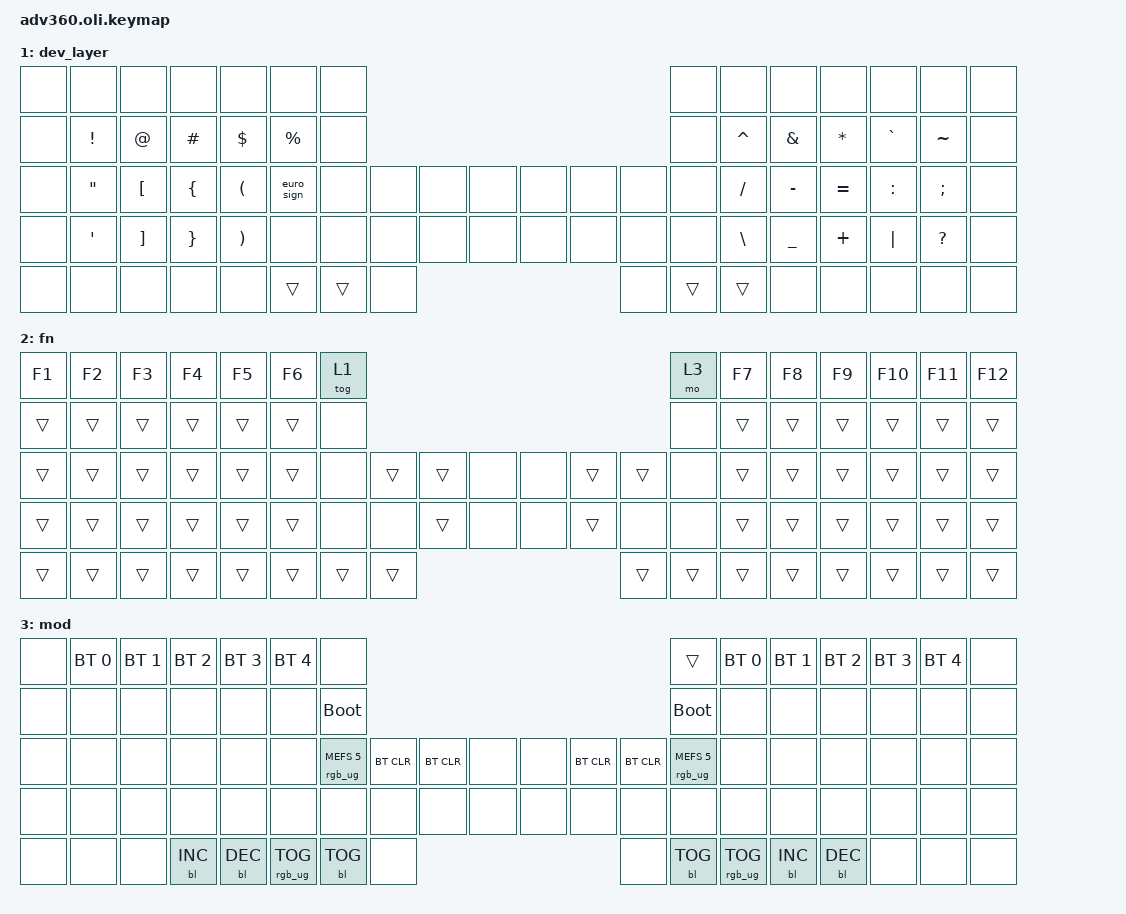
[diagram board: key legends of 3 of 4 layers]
#include <behaviors.dtsi>
#include <dt-bindings/zmk/keys.h>
#include <dt-bindings/zmk/bt.h>
#include <dt-bindings/zmk/rgb.h>
#include <dt-bindings/zmk/backlight.h>

#include "../lib/myHelper.h"
#include "../lib/foreignHelper.h"
#include "../lib/specialChars.dtsi"

// / { 
//     macros {      
//         macro_ue_lower_mac: macro_ue_lower_mac {
//             label = "macro_ue_lower_mac";
//             compatible = "zmk,behavior-macro";
//             wait-ms = <30>;
//             tap-ms = <30>;
//             #binding-cells = <0>;
//             bindings =
//                 <&macro_press &kp LALT>,
//                 <&macro_tap &kp U>,
//                 <&macro_release &kp LALT>,
//                 <&macro_tap &kp U>;
//         };

//         macro_ue_upper_mac: macro_ue_upper_mac {
//             label = "macro_ue_upper_mac";
//             compatible = "zmk,behavior-macro";
//             wait-ms = <20>;
//             tap-ms = <20>;
//             #binding-cells = <0>;
//             bindings =
//                 <&macro_press &kp LALT>,
//                 <&macro_tap &kp U>,
//                 <&macro_release &kp LALT>,
//                 <&macro_tap &kp LC(U)>;
//         };

//         // ZMK_MACRO(ue_lower_mac,
//         //     wait-ms = <30>;
//         //     tap-ms = <30>;
//         //     bindings = 
//         //         <&macro_press &kp LALT>,
//         //         <&macro_tap &kp U>,
//         //         <&macro_release &kp LALT>,
//         //         <&kp U>;
//         // )

//         // ZMK_MACRO(ue_upper_mac,
//         //     wait-ms = <30>;
//         //     tap-ms = <30>;
//         //     bindings =
//         //         <&macro_press &kp LALT>,
//         //         <&macro_tap &kp U>,
//         //         <&macro_release &kp LALT>,
//         //         <&kp LC(U)>;
//         // )
//     };
// };

/ {
    behaviors {
        #include "macros.dtsi"
        
        hm: homerow_mods {
            compatible = "zmk,behavior-hold-tap";
            label = "HOMEROW_MODS";
            #binding-cells = <2>;
            tapping-term-ms = <200>;
            quick_tap_ms = <175>;
            flavor = "tap-preferred";
            bindings = 
                <&kp>,
                <&kp>;
        };

        // macro_ue_lower_mac: macro_ue_lower_mac {
        //     label = "macro_ue_lower_mac";
        //     compatible = "zmk,behavior-macro";
        //     wait-ms = <30>;
        //     tap-ms = <30>;
        //     #binding-cells = <0>;
        //     bindings =
        //         <&macro_press &kp LALT>,
        //         <&macro_tap &kp U>,
        //         <&macro_release &kp LALT>,
        //         <&macro_tap &kp U>;
        // };

        // macro_ue_upper_mac: macro_ue_upper_mac {
        //     label = "macro_ue_upper_mac";
        //     compatible = "zmk,behavior-macro";
        //     wait-ms = <20>;
        //     tap-ms = <20>;
        //     #binding-cells = <0>;
        //     bindings =
        //         <&macro_press &kp LALT>,
        //         <&macro_tap &kp U>,
        //         <&macro_release &kp LALT>,
        //         <&macro_tap &kp LC(U)>;
        // };

        ht: hold_tap {
            label = "hold_tap";
            compatible = "zmk,behavior-hold-tap";
            #binding-cells = <2>;
            flavor = "tap-preferred";
            tapping-term-ms = <200>;
            quick-tap-ms = <160>;
            global-quick-tap;
            bindings = 
                <&kp>,
                <&kp>;
        };

        hts: hold_tap_s {
            label = "hold_tap_s";
            compatible = "zmk,behavior-hold-tap";
            #binding-cells = <2>;
            flavor = "tap-preferred";
            tapping-term-ms = <200>;
            quick-tap-ms = <160>;
            global-quick-tap;
            bindings = 
                <&ue>,
                <&kp>;
        };

        // my_ue: ue_morph {
        //     compatible = "zmk,behavior-mod-morph";
        //     label = "ue_morph";
        //     #binding-cells = <0>;
        //     mods = <(MOD_LSFT|MOD_RSFT)>;
        //     bindings = 
        //         <&macro_ue_lower_mac>, 
        //         <&macro_ue_upper_mac>;
            
        // };
    };

    keymap {
      compatible = "zmk,keymap";

      default_layer {
        bindings = <
        //╭──────────┬──────────┬──────────┬──────────┬──────────┬──────────┬──────────╮                                                                                   ╭──────────╮──────────┬──────────┬──────────┬──────────┬──────────┬──────────╮
            &none      &none      &none      &none      &none      &none      &none                                                                                          &none      &none      &none      &none      &none      &none      &none
        //├──────────┼──────────┼──────────┼──────────┼──────────┼──────────┼──────────┤                                                                                   ├──────────┤──────────┼──────────┼──────────┼──────────┼──────────┼──────────┤
            &none      &kp Q      &kp W      &kp F      &kp P      &kp G      &none                                                                                          &none      &kp J     &kp L       &hts X U  &kp Y      &kp BSPC   &none 
        //├──────────┼──────────┼──────────┼──────────┼──────────┼──────────┼──────────┤            ╭──────────┬──────────╮             ╭──────────╭──────────╮            ├──────────┤──────────┼──────────┼──────────┼──────────┼──────────┼──────────┤
            &none      &kp A      &kp R      &kp S      &kp T      &kp D      &none                   &none      &none      &none &none   &none      &none                   &none      MRR_MAC(H, N,         E,         I)         &kp O      &none
        //├──────────┼──────────┼──────────┼──────────┼──────────┼──────────┼──────────╯ ╭──────────┼──────────┼──────────┤             ├──────────┼──────────┼──────────╮ ╰──────────┤──────────┼──────────┼──────────┼──────────┼──────────┼──────────┤
            &none     MRL_MAC(Z,  X,         C,         V)         &kp B                   &none      &none      &none      &none &none   &none      &none      &none                   &kp K      &kp M      &kp COMMA  &kp DOT    &kp QMARK  &none
        //├──────────┼──────────┼──────────┼──────────┼──────────┼──────────╯            │          │          ├──────────┤             ├──────────│          │          │            ╰──────────┤──────────┼──────────┼──────────┼──────────┼──────────┤
            &none      &none      &none      &none      &none                              &kp SPACE  &tog DEVL  &none                    &none      &tog 2     &kp ENTER                          &none      &none      &none      &none      &none
        //╰──────────┴──────────┴──────────┴──────────┴──────────╯                       ╰──────────┴──────────┴──────────╯             ╰──────────┴──────────╰──────────╯                       ╰──────────┴──────────┴──────────┴──────────┴──────────╯
        >;
      };

      dev_layer {
        bindings = <
        //╭──────────┬──────────┬──────────┬──────────┬──────────┬──────────┬──────────╮                                                                                   ╭──────────╮──────────┬──────────┬──────────┬──────────┬──────────┬──────────╮
        //│          │          │          │          │          │          │          │                                                                                   │          │          │          │          │          │          │          │
            &none      &none      &none      &none      &none      &none      &none                                                                                          &none      &none      &none      &none      &none      &none      &none
        //├──────────┼──────────┼──────────┼──────────┼──────────┼──────────┼──────────┤                                                                                   ├──────────┤──────────┼──────────┼──────────┼──────────┼──────────┼──────────┤
        //│          │ !        │ @        │ #        │ $        │ %        │          │                                                                                   │          │ ^        │ &        │ *        │ `        │ ~        │          │
            &none      &kp EXCL   &kp AT     &kp HASH   &kp DLLR   &kp PRCNT  &none                                                                                          &none      &kp CARET  &kp AMPS   &kp ASTRK  &kp GRAVE  &kp TILDE  &none
        //├──────────┼──────────┼──────────┼──────────┼──────────┼──────────┼──────────┤            ╭──────────┬──────────╮             ╭──────────╭──────────╮            ├──────────┤──────────┼──────────┼──────────┼──────────┼──────────┼──────────┤
        //│          │ "        │ [        │ {        │ (        │          │          │            │          │          │             │          │          │            │          │ /        │ -        │ =        │ :        │ ;        │          │
            &none      &kp DQT    &kp LBKT   &kp LBRC   &kp LPAR   &euro_sign &none                   &none      &none      &none &none   &none      &none                   &none      &kp FSLH   &kp MINUS  &kp EQUAL  &kp COLON  &kp SEMI   &none
        //├──────────┼──────────┼──────────┼──────────┼──────────┼──────────┼──────────╯ ╭──────────┼──────────┼──────────┤             ├──────────┼──────────┼──────────╮ ╰──────────┤──────────┼──────────┼──────────┼──────────┼──────────┼──────────┤
        //│          │ '        │ ]        │ }        │ (        │          │            │          │          │          │             │          │          │          │            │ \        │ _        │ +        │ |        │ ?        │          │
            &none      &kp SQT     &kp RBKT   &kp RBRC   &kp RPAR  &none                   &none      &none      &none      &none &none   &none      &none      &none                   &kp BSLH   &kp UNDER  &kp PLUS   &kp PIPE   &kp QMARK  &none
        //├──────────┼──────────┼──────────┼──────────┼──────────┼──────────╯            │          │          ├──────────┤             ├──────────│          │          │            ╰──────────┤──────────┼──────────┼──────────┼──────────┼──────────┤
        //│          │          │          │          │          │                       │ SPACE    │ Layer    │          │             │          │ Layer    │ ENTER    │                       │          │          │          │          │          │
            &none      &none      &none      &none      &none                              &trans     &trans     &none                    &none      &trans     &trans                             &none      &none      &none      &none      &none
        //╰──────────┴──────────┴──────────┴──────────┴──────────╯                       ╰──────────┴──────────┴──────────╯             ╰──────────┴──────────╰──────────╯                       ╰──────────┴──────────┴──────────┴──────────┴──────────╯
        >;
      };
 
      // default_layer {
      //   bindings = <
      //     &kp EQUAL &kp N1    &kp N2   &kp N3   &kp N4     &kp N5 &tog 1                                                                       &mo 3 &kp N6 &kp N7 &kp N8    &kp N9   &kp N0   &kp MINUS
      //     &kp TAB   &kp Q     &kp W    &kp E    &kp R      &kp T  &none                                                                        &none &kp Y  &kp U  &kp I     &kp O    &kp P    &kp BSLH
      //     &kp ESC   &kp A     &kp S    &kp D    &kp F      &kp G  &none           &kp LCTRL &kp LALT &none &none &kp LGUI  &kp RCTRL           &none &kp H  &kp J  &kp K     &kp L    &kp SEMI &kp SQT
      //     &kp LSHFT &kp Z     &kp X    &kp C    &kp V      &kp B         &none    &none     &kp HOME &none &none &kp PG_UP &none     &none           &kp N  &kp M  &kp COMMA &kp DOT  &kp FSLH &kp RSHFT
      //     &mo 2     &kp GRAVE &kp CAPS &kp LEFT &kp RIGHT                &kp BSPC &kp DEL   &kp END              &kp PG_DN &kp ENTER &kp SPACE              &kp UP &kp DOWN  &kp LBKT &kp RBKT &mo 2
      //   >;
      // };

      // keypad {
      //   bindings = <
      //     &kp EQUAL &kp N1    &kp N2   &kp N3   &kp N4     &kp N5 &trans                                                                       &mo 3 &kp N6 &kp KP_NUM &kp KP_EQUAL &kp KP_DIVIDE &kp KP_MULTIPLY &kp MINUS
      //     &kp TAB   &kp Q     &kp W    &kp E    &kp R      &kp T  &none                                                                        &none &kp Y  &kp KP_N7  &kp KP_N8    &kp KP_N9     &kp KP_MINUS    &kp BSLH
      //     &kp ESC   &kp A     &kp S    &kp D    &kp F      &kp G  &none           &kp LCTRL &kp LALT &none &none &kp LGUI  &kp RCTRL           &none &kp H  &kp KP_N4  &kp KP_N5    &kp KP_N6     &kp KP_PLUS     &kp SQT
      //     &kp LSHFT &kp Z     &kp X    &kp C    &kp V      &kp B         &none    &none     &kp HOME &none &none &kp PG_UP &none     &none           &kp N  &kp KP_N1  &kp KP_N2    &kp KP_N3     &kp KP_ENTER    &kp RSHFT
      //     &mo 2     &kp GRAVE &kp CAPS &kp LEFT &kp RIGHT                &kp BSPC &kp DEL   &kp END              &kp PG_DN &kp ENTER &kp KP_N0              &kp UP     &kp DOWN     &kp KP_DOT    &kp RBKT        &mo 2
      //   >;
      // };

      fn {
        bindings = <
          &kp F1 &kp F2 &kp F3 &kp F4 &kp F5 &kp F6 &tog 1                                                       &mo 3 &kp F7 &kp F8 &kp F9 &kp F10 &kp F11 &kp F12
          &trans &trans &trans &trans &trans &trans  &none                                                       &none &trans &trans &trans &trans  &trans  &trans
          &trans &trans &trans &trans &trans &trans  &none        &trans &trans &none &none &trans &trans        &none &trans &trans &trans &trans  &trans  &trans
          &trans &trans &trans &trans &trans &trans        &none  &none  &trans &none &none &trans &none  &none        &trans &trans &trans &trans  &trans  &trans
          &trans &trans &trans &trans &trans               &trans &trans &trans             &trans &trans &trans              &trans &trans &trans  &trans  &trans
        >;
      };

      mod {
        bindings = <
          &none &bt BT_SEL 0 &bt BT_SEL 1 &bt BT_SEL 2 &bt BT_SEL 3 &bt BT_SEL 4 &none                                                                                                          &trans                 &bt BT_SEL 0 &bt BT_SEL 1 &bt BT_SEL 2 &bt BT_SEL 3 &bt BT_SEL 4 &none
          &none &none        &none        &none        &none        &none        &bootloader                                                                                                    &bootloader            &none        &none        &none        &none        &none        &none
          &none &none        &none        &none        &none        &none        &rgb_ug RGB_MEFS_CMD 5                 &bt BT_CLR &bt BT_CLR &none &none &bt BT_CLR &bt BT_CLR                 &rgb_ug RGB_MEFS_CMD 5 &none        &none        &none        &none        &none        &none
          &none &none        &none        &none        &none        &none                               &none           &none      &none      &none &none &none      &none      &none                                  &none        &none        &none        &none        &none        &none
          &none &none        &none        &bl BL_INC   &bl BL_DEC                                       &rgb_ug RGB_TOG &bl BL_TOG &none                  &none      &bl BL_TOG &rgb_ug RGB_TOG                                     &bl BL_INC   &bl BL_DEC   &none        &none        &none
        >;
      };
  };
};
